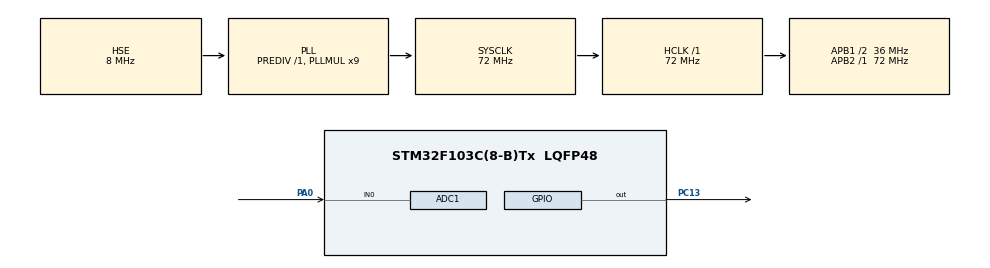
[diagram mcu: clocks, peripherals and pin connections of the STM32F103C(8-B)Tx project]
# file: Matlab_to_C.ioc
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ADC1.Channel-2\#ChannelRegularConversion=ADC_CHANNEL_0
ADC1.ContinuousConvMode=DISABLE
ADC1.EnableRegularConversion=ENABLE
ADC1.ExternalTrigConv=ADC_EXTERNALTRIGCONV_T3_TRGO
ADC1.NbrOfConversionFlag=1
ADC1.Rank-2\#ChannelRegularConversion=1
ADC1.SamplingTime-2\#ChannelRegularConversion=ADC_SAMPLETIME_1CYCLE_5
ADC1.master=1
Dma.ADC1.0.Direction=DMA_PERIPH_TO_MEMORY
Dma.ADC1.0.Instance=DMA1_Channel1
Dma.ADC1.0.MemDataAlignment=DMA_MDATAALIGN_WORD
Dma.ADC1.0.MemInc=DMA_MINC_ENABLE
Dma.ADC1.0.Mode=DMA_CIRCULAR
Dma.ADC1.0.PeriphDataAlignment=DMA_PDATAALIGN_WORD
Dma.ADC1.0.PeriphInc=DMA_PINC_DISABLE
Dma.ADC1.0.Priority=DMA_PRIORITY_LOW
Dma.Request0=ADC1
Mcu.Family=STM32F1
Mcu.Name=STM32F103C(8-B)Tx
Mcu.Package=LQFP48
NVIC.ADC1_2_IRQn=true\:0\:0\:false\:false\:true\:true\:true\:true
NVIC.DMA1_Channel1_IRQn=true\:0\:0\:false\:false\:true\:false\:true\:true
NVIC.PriorityGroup=NVIC_PRIORITYGROUP_4
PA0-WKUP.Signal=ADCx_IN0
PA13.Mode=Serial_Wire
PA13.Signal=SYS_JTMS-SWDIO
PA14.Mode=Serial_Wire
PA14.Signal=SYS_JTCK-SWCLK
PC13-TAMPER-RTC.Signal=GPIO_Output
PD0-OSC_IN.Mode=HSE-External-Oscillator
PD0-OSC_IN.Signal=RCC_OSC_IN
PD1-OSC_OUT.Mode=HSE-External-Oscillator
PD1-OSC_OUT.Signal=RCC_OSC_OUT
ProjectManager.HeapSize=0x200
ProjectManager.StackSize=0x400
ProjectManager.TargetToolchain=STM32CubeIDE
RCC.ADCPresc=RCC_ADCPCLK2_DIV8
RCC.AHBFreq_Value=72000000
RCC.APB1CLKDivider=RCC_HCLK_DIV2
RCC.APB1Freq_Value=36000000
RCC.APB1TimFreq_Value=72000000
RCC.APB2Freq_Value=72000000
RCC.APB2TimFreq_Value=72000000
RCC.HCLKFreq_Value=72000000
RCC.PLLMUL=RCC_PLL_MUL9
RCC.PLLSourceVirtual=RCC_PLLSOURCE_HSE
RCC.SYSCLKFreq_VALUE=72000000
RCC.SYSCLKSource=RCC_SYSCLKSOURCE_PLLCLK
RCC.USBFreq_Value=72000000
SH.ADCx_IN0.0=ADC1_IN0,IN0
TIM3.AutoReloadPreload=TIM_AUTORELOAD_PRELOAD_DISABLE
TIM3.Channel-Output\ Compare1\ No\ Output=TIM_CHANNEL_1
TIM3.Period=10285
TIM3.Prescaler=0
TIM3.TIM_MasterOutputTrigger=TIM_TRGO_UPDATE
VP_TIM3_VS_ClockSourceINT.Mode=Internal
VP_TIM3_VS_no_output1.Mode=Output Compare1 No Output
board=custom

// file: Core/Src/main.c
/* USER CODE BEGIN Header */
/**
  ******************************************************************************
  * @file           : main.c
  * @brief          : Main program body
  ******************************************************************************
  * @attention
  *
  * Copyright (c) 2022 STMicroelectronics.
  * All rights reserved.
  *
  * This software is licensed under terms that can be found in the LICENSE file
  * in the root directory of this software component.
  * If no LICENSE file comes with this software, it is provided AS-IS.
  *
  ******************************************************************************
  */
/* USER CODE END Header */
#include "main.h"

/* USER CODE BEGIN Includes */
#include "main.h"
#include "functions.h"
#include "bacf.h"
#include "dwt.h"
#include "adc_signal.h"
#include "dsp.h"
/* USER CODE END Includes */

/* USER CODE BEGIN PD */

/* USER CODE END PTD */

/* Private define ------------------------------------------------------------*/
/* USER CODE BEGIN PD */
/* USER CODE END PD */

 ADC_HandleTypeDef hadc1;
DMA_HandleTypeDef hdma_adc1;

TIM_HandleTypeDef htim3;

void SystemClock_Config(void);
static void MX_GPIO_Init(void);
static void MX_ADC1_Init(void);
static void MX_DMA_Init(void);
static void MX_TIM3_Init(void);

/* USER CODE BEGIN 0 */
uint32_t ADC_Value;
uint8_t datos_listos = 0;
uint32_t volatile ticks=0;

uint32_t ADC_Buffer[ADC_BUF_LEN];
uint32_t temp_out_buffer[ADC_BUF_LEN/2];
uint32_t zcvec [ADC_BUF_SALIDA_LEN];
//extern uint32_t ADC_Buffer2[ADC_BUF_LEN];

void HAL_ADC_ConvCpltCallback(ADC_HandleTypeDef* hadc){//Cuando se llena el buffer se llama a este callback

	ticks = dwt_read();
	dwt_reset();
	datos_listos = 1;
	HAL_ADC_Stop_DMA(&hadc1);//desactivo el ADC para que no interrumpa el procesamiento
	//HAL_GPIO_TogglePin(GPIOC, GPIO_PIN_13);

}

/* USER CODE END 0 */

int main(void)
{

  /* MCU Configuration--------------------------------------------------------*/

  /* Reset of all peripherals, Initializes the Flash interface and the Systick. */
  HAL_Init();

  /* Configure the system clock */
  SystemClock_Config();

  /* Initialize all configured peripherals */
  MX_GPIO_Init();
  MX_DMA_Init();
  MX_ADC1_Init();
  MX_TIM3_Init();
  /* USER CODE BEGIN 2 */

  HAL_TIM_Base_Start(&htim3);
  HAL_ADC_Start_DMA(&hadc1,ADC_Buffer, ADC_BUF_LEN);
  dwt_inic();

  /* USER CODE END 2 */

  /* Infinite loop */
  /* USER CODE BEGIN WHILE */
  while (1)
  {

	if(datos_listos){
		zero_cross_hyst(ADC_Buffer2,zcvec);
		BACF_Compute_1(zcvec, temp_out_buffer, ADC_BUF_LEN);
		freq_detect(temp_out_buffer,ADC_BUF_LEN/2,300,50);
		datos_listos = 0;
		HAL_ADC_Start_DMA(&hadc1,ADC_Buffer, ADC_BUF_LEN);
		closest_period()
	}

    /* USER CODE END WHILE */

  }
}

void SystemClock_Config(void)
{
  RCC_OscInitTypeDef RCC_OscInitStruct = {0};
  RCC_ClkInitTypeDef RCC_ClkInitStruct = {0};
  RCC_PeriphCLKInitTypeDef PeriphClkInit = {0};

  /** Initializes the RCC Oscillators according to the specified parameters
  * in the RCC_OscInitTypeDef structure.
  */
  RCC_OscInitStruct.OscillatorType = RCC_OSCILLATORTYPE_HSE;
  RCC_OscInitStruct.HSEState = RCC_HSE_ON;
  RCC_OscInitStruct.HSEPredivValue = RCC_HSE_PREDIV_DIV1;
  RCC_OscInitStruct.HSIState = RCC_HSI_ON;
  RCC_OscInitStruct.PLL.PLLState = RCC_PLL_ON;
  RCC_OscInitStruct.PLL.PLLSource = RCC_PLLSOURCE_HSE;
  RCC_OscInitStruct.PLL.PLLMUL = RCC_PLL_MUL9;
  if (HAL_RCC_OscConfig(&RCC_OscInitStruct) != HAL_OK)
  {
    Error_Handler();
  }

  /** Initializes the CPU, AHB and APB buses clocks
  */
  RCC_ClkInitStruct.ClockType = RCC_CLOCKTYPE_HCLK|RCC_CLOCKTYPE_SYSCLK
                              |RCC_CLOCKTYPE_PCLK1|RCC_CLOCKTYPE_PCLK2;
  RCC_ClkInitStruct.SYSCLKSource = RCC_SYSCLKSOURCE_PLLCLK;
  RCC_ClkInitStruct.AHBCLKDivider = RCC_SYSCLK_DIV1;
  RCC_ClkInitStruct.APB1CLKDivider = RCC_HCLK_DIV2;
  RCC_ClkInitStruct.APB2CLKDivider = RCC_HCLK_DIV1;

  if (HAL_RCC_ClockConfig(&RCC_ClkInitStruct, FLASH_LATENCY_2) != HAL_OK)
  {
    Error_Handler();
  }
  PeriphClkInit.PeriphClockSelection = RCC_PERIPHCLK_ADC;
  PeriphClkInit.AdcClockSelection = RCC_ADCPCLK2_DIV8;
  if (HAL_RCCEx_PeriphCLKConfig(&PeriphClkInit) != HAL_OK)
  {
    Error_Handler();
  }
}

static void MX_ADC1_Init(void)
{

  ADC_ChannelConfTypeDef sConfig = {0};

  /** Common config
  */
  hadc1.Instance = ADC1;
  hadc1.Init.ScanConvMode = ADC_SCAN_DISABLE;
  hadc1.Init.ContinuousConvMode = DISABLE;
  hadc1.Init.DiscontinuousConvMode = DISABLE;
  hadc1.Init.ExternalTrigConv = ADC_EXTERNALTRIGCONV_T3_TRGO;
  hadc1.Init.DataAlign = ADC_DATAALIGN_RIGHT;
  hadc1.Init.NbrOfConversion = 1;
  if (HAL_ADC_Init(&hadc1) != HAL_OK)
  {
    Error_Handler();
  }

  /** Configure Regular Channel
  */
  sConfig.Channel = ADC_CHANNEL_0;
  sConfig.Rank = ADC_REGULAR_RANK_1;
  sConfig.SamplingTime = ADC_SAMPLETIME_1CYCLE_5;
  if (HAL_ADC_ConfigChannel(&hadc1, &sConfig) != HAL_OK)
  {
    Error_Handler();
  }

}

static void MX_TIM3_Init(void)
{

  TIM_ClockConfigTypeDef sClockSourceConfig = {0};
  TIM_MasterConfigTypeDef sMasterConfig = {0};
  TIM_OC_InitTypeDef sConfigOC = {0};

  htim3.Instance = TIM3;
  htim3.Init.Prescaler = 0;
  htim3.Init.CounterMode = TIM_COUNTERMODE_UP;
  htim3.Init.Period = 10285;
  htim3.Init.ClockDivision = TIM_CLOCKDIVISION_DIV1;
  htim3.Init.AutoReloadPreload = TIM_AUTORELOAD_PRELOAD_DISABLE;
  if (HAL_TIM_Base_Init(&htim3) != HAL_OK)
  {
    Error_Handler();
  }
  sClockSourceConfig.ClockSource = TIM_CLOCKSOURCE_INTERNAL;
  if (HAL_TIM_ConfigClockSource(&htim3, &sClockSourceConfig) != HAL_OK)
  {
    Error_Handler();
  }
  if (HAL_TIM_OC_Init(&htim3) != HAL_OK)
  {
    Error_Handler();
  }
  sMasterConfig.MasterOutputTrigger = TIM_TRGO_UPDATE;
  sMasterConfig.MasterSlaveMode = TIM_MASTERSLAVEMODE_DISABLE;
  if (HAL_TIMEx_MasterConfigSynchronization(&htim3, &sMasterConfig) != HAL_OK)
  {
    Error_Handler();
  }
  sConfigOC.OCMode = TIM_OCMODE_TIMING;
  sConfigOC.Pulse = 0;
  sConfigOC.OCPolarity = TIM_OCPOLARITY_HIGH;
  sConfigOC.OCFastMode = TIM_OCFAST_DISABLE;
  if (HAL_TIM_OC_ConfigChannel(&htim3, &sConfigOC, TIM_CHANNEL_1) != HAL_OK)
  {
    Error_Handler();
  }

}

static void MX_DMA_Init(void)
{

  /* DMA controller clock enable */
  __HAL_RCC_DMA1_CLK_ENABLE();

  /* DMA interrupt init */
  /* DMA1_Channel1_IRQn interrupt configuration */
  HAL_NVIC_SetPriority(DMA1_Channel1_IRQn, 0, 0);
  HAL_NVIC_EnableIRQ(DMA1_Channel1_IRQn);

}

static void MX_GPIO_Init(void)
{
  GPIO_InitTypeDef GPIO_InitStruct = {0};

  /* GPIO Ports Clock Enable */
  __HAL_RCC_GPIOC_CLK_ENABLE();
  __HAL_RCC_GPIOD_CLK_ENABLE();
  __HAL_RCC_GPIOA_CLK_ENABLE();

  /*Configure GPIO pin Output Level */
  HAL_GPIO_WritePin(GPIOC, GPIO_PIN_13, GPIO_PIN_RESET);

  /*Configure GPIO pin : PC13 */
  GPIO_InitStruct.Pin = GPIO_PIN_13;
  GPIO_InitStruct.Mode = GPIO_MODE_OUTPUT_PP;
  GPIO_InitStruct.Pull = GPIO_NOPULL;
  GPIO_InitStruct.Speed = GPIO_SPEED_FREQ_LOW;
  HAL_GPIO_Init(GPIOC, &GPIO_InitStruct);

}

void Error_Handler(void)
{
  __disable_irq();
  while (1)
  {
  }
}
